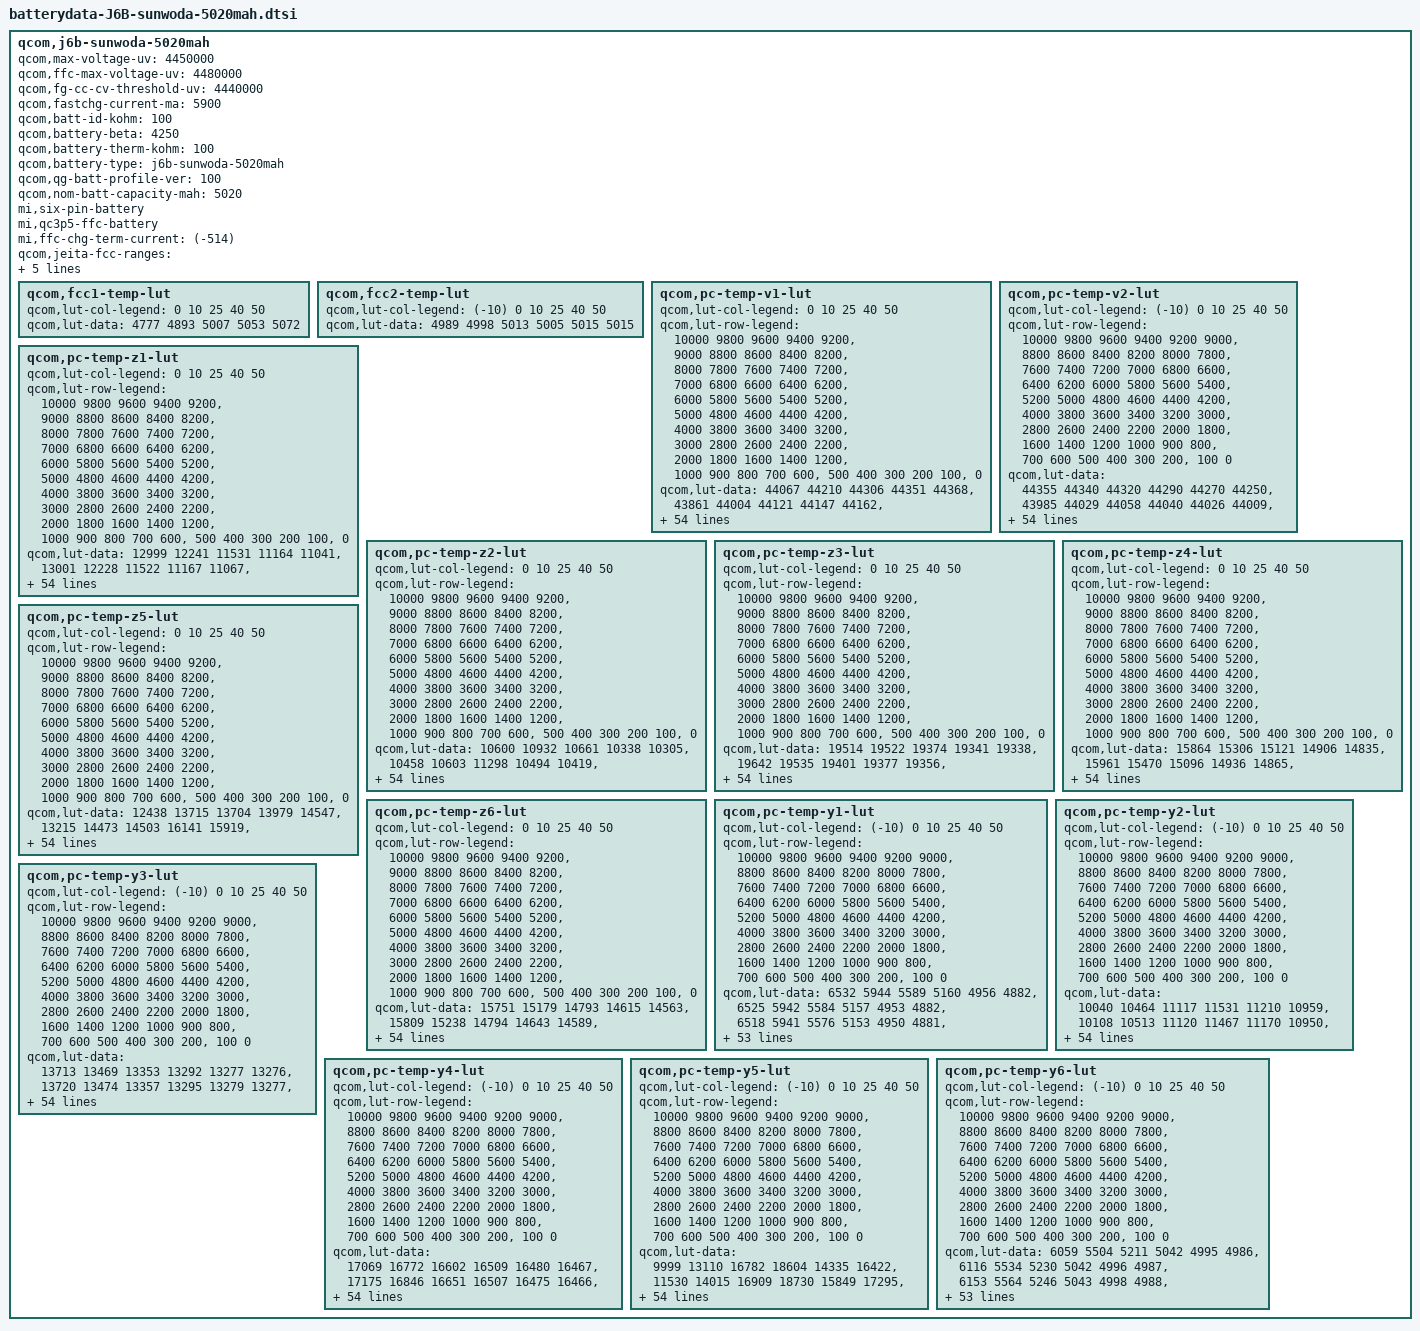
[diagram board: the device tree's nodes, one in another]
/*
 * Copyright (c) 2019, The Linux Foundation. All rights reserved.
 * Copyright (C) 2020 XiaoMi, Inc.
 *
 * This program is free software; you can redistribute it and/or modify
 * it under the terms of the GNU General Public License version 2 and
 * only version 2 as published by the Free Software Foundation.
 *
 * This program is distributed in the hope that it will be useful,
 * but WITHOUT ANY WARRANTY; without even the implied warranty of
 * MERCHANTABILITY or FITNESS FOR A PARTICULAR PURPOSE.  See the
 * GNU General Public License for more details.
 */

qcom,j6b-sunwoda-5020mah {
	/* 4322231_LC_M524_Sunwoda_5020mAH_PM6250_averaged_MasterSlave_Dec20th2019 */
	qcom,max-voltage-uv = <4450000>;
	qcom,ffc-max-voltage-uv = <4480000>;
	qcom,fg-cc-cv-threshold-uv = <4440000>;
	qcom,fastchg-current-ma = <5900>;
	qcom,batt-id-kohm = <100>;
	qcom,battery-beta = <4250>;
	qcom,battery-therm-kohm = <100>;
	qcom,battery-type = "j6b-sunwoda-5020mah";
	qcom,qg-batt-profile-ver = <100>;
	qcom,nom-batt-capacity-mah = <5020>;
	mi,six-pin-battery;
	mi,qc3p5-ffc-battery;
	mi,ffc-chg-term-current = <(-514)>;

	qcom,jeita-fcc-ranges = <0  50   900000
				51  100  2300000
				101 150  3300000
				151 450  5900000
				451 580  2300000>;

	qcom,jeita-fv-ranges = <0   50   4450000
				51  100  4450000
				101 150  4450000
				151 450  4480000
				451 580  4100000>;

	qcom,step-chg-ranges = <3001000  4250000  6000000
				4250001  4450000  4900000
				4450001  4480000  3900000>;

	qcom,fcc1-temp-lut {
		qcom,lut-col-legend = <0 10 25 40 50>;
		qcom,lut-data = <4777 4893 5007 5053 5072>;
	};

	qcom,fcc2-temp-lut {
		qcom,lut-col-legend = <(-10) 0 10 25 40 50>;
		qcom,lut-data = <4989 4998 5013 5005 5015 5015>;
	};

	qcom,pc-temp-v1-lut {
		qcom,lut-col-legend = <0 10 25 40 50>;
		qcom,lut-row-legend = <10000 9800 9600 9400 9200>,
			<9000 8800 8600 8400 8200>,
			<8000 7800 7600 7400 7200>,
			<7000 6800 6600 6400 6200>,
			<6000 5800 5600 5400 5200>,
			<5000 4800 4600 4400 4200>,
			<4000 3800 3600 3400 3200>,
			<3000 2800 2600 2400 2200>,
			<2000 1800 1600 1400 1200>,
			<1000 900 800 700 600>,
			<500 400 300 200 100>,
			<0>;
		qcom,lut-data = <44067 44210 44306 44351 44368>,
			<43861 44004 44121 44147 44162>,
			<43640 43794 43925 43950 43963>,
			<43411 43583 43717 43748 43762>,
			<43173 43361 43496 43539 43553>,
			<42929 43123 43266 43324 43339>,
			<42688 42877 43027 43095 43114>,
			<42445 42633 42783 42854 42878>,
			<42207 42387 42539 42611 42637>,
			<41973 42145 42294 42365 42392>,
			<41744 41910 42051 42118 42145>,
			<41520 41679 41810 41878 41902>,
			<41299 41453 41573 41640 41660>,
			<41084 41229 41343 41406 41425>,
			<40873 41012 41119 41176 41198>,
			<40668 40803 40902 40953 40978>,
			<40467 40599 40694 40738 40763>,
			<40265 40404 40492 40531 40553>,
			<40072 40216 40301 40335 40353>,
			<39902 40032 40120 40157 40172>,
			<39753 39853 39927 39974 39989>,
			<39603 39677 39696 39742 39766>,
			<39440 39478 39456 39478 39507>,
			<39269 39208 39240 39261 39288>,
			<39102 38954 39036 39085 39113>,
			<38927 38811 38877 38936 38963>,
			<38769 38714 38769 38814 38835>,
			<38656 38636 38682 38710 38724>,
			<38569 38569 38595 38610 38617>,
			<38499 38510 38512 38509 38509>,
			<38443 38454 38436 38416 38410>,
			<38397 38400 38365 38333 38325>,
			<38357 38349 38299 38256 38249>,
			<38322 38301 38238 38187 38177>,
			<38290 38255 38181 38124 38108>,
			<38256 38213 38127 38064 38041>,
			<38222 38176 38080 38007 37974>,
			<38179 38134 38034 37949 37906>,
			<38113 38067 37967 37876 37823>,
			<38026 37973 37872 37777 37718>,
			<37923 37866 37763 37666 37602>,
			<37789 37739 37644 37551 37481>,
			<37638 37593 37508 37421 37347>,
			<37464 37415 37340 37259 37184>,
			<37343 37262 37192 37117 37049>,
			<37244 37163 37097 37025 36971>,
			<37203 37137 37069 37002 36943>,
			<37171 37123 37048 36982 36927>,
			<37140 37094 37030 36965 36904>,
			<37081 37047 36976 36904 36833>,
			<36869 36828 36724 36638 36547>,
			<36411 36379 36276 36194 36103>,
			<35819 35795 35687 35615 35521>,
			<35010 34998 34879 34820 34728>,
			<33721 33737 33606 33581 33488>,
			<30000 30000 30000 30000 30000>;
	};

	qcom,pc-temp-v2-lut {
		qcom,lut-col-legend = <(-10) 0 10 25 40 50>;
		qcom,lut-row-legend = <10000 9800 9600 9400 9200 9000>,
			<8800 8600 8400 8200 8000 7800>,
			<7600 7400 7200 7000 6800 6600>,
			<6400 6200 6000 5800 5600 5400>,
			<5200 5000 4800 4600 4400 4200>,
			<4000 3800 3600 3400 3200 3000>,
			<2800 2600 2400 2200 2000 1800>,
			<1600 1400 1200 1000 900 800>,
			<700 600 500 400 300 200>,
			<100 0>;
		qcom,lut-data = <44355 44340 44320 44290 44270 44250>,
			<43985 44029 44058 44040 44026 44009>,
			<43650 43745 43809 43799 43790 43776>,
			<43359 43493 43577 43569 43565 43552>,
			<43109 43273 43363 43351 43350 43339>,
			<42862 43050 43143 43129 43131 43120>,
			<42590 42805 42902 42889 42895 42886>,
			<42316 42549 42651 42642 42653 42645>,
			<42065 42291 42402 42397 42409 42403>,
			<41828 42029 42151 42154 42164 42159>,
			<41613 41768 41904 41913 41921 41916>,
			<41436 41494 41661 41673 41682 41677>,
			<41269 41232 41423 41436 41445 41441>,
			<41057 41048 41191 41205 41214 41211>,
			<40782 40931 40966 40980 40990 40986>,
			<40477 40790 40753 40762 40772 40767>,
			<40138 40515 40565 40550 40561 40556>,
			<39778 40156 40382 40344 40358 40352>,
			<39502 39873 40164 40148 40163 40158>,
			<39295 39648 39901 39967 39982 39978>,
			<39099 39436 39642 39771 39787 39785>,
			<38862 39216 39407 39522 39547 39549>,
			<38624 39002 39186 39253 39292 39300>,
			<38470 38804 38992 39041 39081 39092>,
			<38372 38618 38818 38870 38901 38912>,
			<38293 38450 38662 38722 38746 38756>,
			<38221 38290 38524 38591 38615 38624>,
			<38157 38147 38400 38476 38502 38508>,
			<38098 38062 38285 38368 38397 38403>,
			<38043 38012 38176 38267 38301 38306>,
			<37989 37970 38077 38175 38214 38216>,
			<37929 37926 37982 38094 38134 38136>,
			<37867 37883 37897 38019 38059 38059>,
			<37801 37838 37838 37948 37984 37980>,
			<37733 37792 37799 37880 37909 37898>,
			<37661 37742 37762 37812 37828 37809>,
			<37584 37685 37725 37739 37731 37700>,
			<37503 37623 37686 37662 37625 37583>,
			<37421 37551 37631 37582 37529 37479>,
			<37337 37471 37553 37501 37441 37387>,
			<37255 37378 37455 37412 37348 37293>,
			<37179 37264 37328 37306 37247 37190>,
			<37108 37133 37180 37184 37134 37077>,
			<37040 36997 37026 37040 36992 36936>,
			<36968 36875 36896 36925 36886 36833>,
			<36881 36788 36811 36870 36838 36788>,
			<36826 36751 36773 36852 36826 36775>,
			<36763 36714 36733 36832 36810 36759>,
			<36689 36669 36676 36795 36780 36728>,
			<36577 36585 36573 36708 36691 36621>,
			<36371 36391 36336 36413 36374 36275>,
			<35995 35997 35894 35911 35878 35770>,
			<35394 35373 35269 35245 35221 35101>,
			<34516 34482 34387 34317 34298 34172>,
			<33069 32970 32916 32764 32899 32759>,
			<28712 28026 28771 27555 28520 28438>;
	};

	qcom,pc-temp-z1-lut {
		qcom,lut-col-legend = <0 10 25 40 50>;
		qcom,lut-row-legend = <10000 9800 9600 9400 9200>,
			<9000 8800 8600 8400 8200>,
			<8000 7800 7600 7400 7200>,
			<7000 6800 6600 6400 6200>,
			<6000 5800 5600 5400 5200>,
			<5000 4800 4600 4400 4200>,
			<4000 3800 3600 3400 3200>,
			<3000 2800 2600 2400 2200>,
			<2000 1800 1600 1400 1200>,
			<1000 900 800 700 600>,
			<500 400 300 200 100>,
			<0>;
		qcom,lut-data = <12999 12241 11531 11164 11041>,
			<13001 12228 11522 11167 11067>,
			<13008 12216 11513 11162 11055>,
			<13008 12203 11506 11157 11045>,
			<12987 12186 11492 11152 11042>,
			<12957 12164 11478 11145 11039>,
			<12933 12141 11465 11139 11035>,
			<12910 12122 11453 11133 11032>,
			<12899 12107 11441 11129 11029>,
			<12902 12093 11430 11125 11027>,
			<12906 12078 11423 11122 11025>,
			<12902 12063 11419 11121 11024>,
			<12868 12052 11417 11121 11024>,
			<12828 12041 11416 11120 11023>,
			<12804 12033 11416 11120 11023>,
			<12786 12030 11416 11119 11024>,
			<12767 12028 11416 11119 11024>,
			<12744 12025 11417 11120 11026>,
			<12724 12019 11418 11121 11027>,
			<12717 12015 11420 11122 11028>,
			<12713 12017 11423 11123 11029>,
			<12712 12023 11426 11125 11030>,
			<12718 12028 11429 11126 11031>,
			<12735 12031 11433 11128 11032>,
			<12744 12035 11436 11129 11034>,
			<12745 12040 11440 11131 11036>,
			<12744 12046 11444 11133 11038>,
			<12741 12050 11449 11137 11041>,
			<12738 12054 11453 11141 11044>,
			<12736 12057 11457 11145 11048>,
			<12747 12060 11462 11149 11051>,
			<12764 12063 11468 11153 11054>,
			<12768 12068 11474 11157 11058>,
			<12758 12073 11480 11162 11062>,
			<12749 12079 11485 11166 11065>,
			<12752 12087 11491 11170 11068>,
			<12767 12099 11497 11174 11072>,
			<12781 12111 11502 11178 11075>,
			<12797 12119 11509 11182 11078>,
			<12813 12125 11517 11186 11082>,
			<12826 12132 11525 11190 11086>,
			<12847 12140 11533 11195 11089>,
			<12858 12152 11542 11200 11092>,
			<12870 12177 11558 11205 11096>,
			<12870 12200 11579 11214 11100>,
			<12891 12195 11585 11217 11104>,
			<12871 12189 11587 11216 11103>,
			<12883 12199 11588 11219 11103>,
			<12901 12186 11592 11221 11106>,
			<12895 12212 11601 11227 11109>,
			<12889 12207 11611 11233 11114>,
			<12906 12228 11622 11241 11120>,
			<12923 12251 11635 11250 11129>,
			<12945 12273 11653 11265 11141>,
			<12945 12273 11653 11265 11141>,
			<12945 12273 11653 11265 11141>;
	};

	qcom,pc-temp-z2-lut {
		qcom,lut-col-legend = <0 10 25 40 50>;
		qcom,lut-row-legend = <10000 9800 9600 9400 9200>,
			<9000 8800 8600 8400 8200>,
			<8000 7800 7600 7400 7200>,
			<7000 6800 6600 6400 6200>,
			<6000 5800 5600 5400 5200>,
			<5000 4800 4600 4400 4200>,
			<4000 3800 3600 3400 3200>,
			<3000 2800 2600 2400 2200>,
			<2000 1800 1600 1400 1200>,
			<1000 900 800 700 600>,
			<500 400 300 200 100>,
			<0>;
		qcom,lut-data = <10600 10932 10661 10338 10305>,
			<10458 10603 11298 10494 10419>,
			<10419 10572 11598 10572 10488>,
			<10398 10561 11457 10595 10520>,
			<10369 10544 10904 10573 10502>,
			<10342 10508 10605 10534 10468>,
			<10334 10465 10555 10488 10437>,
			<10331 10436 10516 10429 10386>,
			<10330 10411 10489 10407 10356>,
			<10335 10400 10468 10414 10361>,
			<10342 10401 10460 10422 10371>,
			<10347 10405 10471 10418 10375>,
			<10351 10414 10494 10406 10387>,
			<10356 10449 10559 10401 10393>,
			<10363 10485 10728 10411 10298>,
			<10373 10504 10847 10423 10173>,
			<10387 10521 10901 10437 10164>,
			<10412 10543 10939 10459 10195>,
			<10446 10584 10903 10462 10224>,
			<10483 10616 10725 10399 10244>,
			<10529 10619 10636 10338 10269>,
			<10561 10619 10716 10447 10379>,
			<10567 10622 10816 10724 10634>,
			<10571 10649 10814 10802 10737>,
			<10576 10679 10727 10578 10577>,
			<10592 10679 10669 10373 10402>,
			<10611 10666 10664 10400 10402>,
			<10625 10658 10668 10490 10448>,
			<10637 10666 10690 10576 10500>,
			<10646 10679 10753 10718 10589>,
			<10654 10690 10787 10820 10659>,
			<10660 10699 10776 10767 10609>,
			<10669 10707 10757 10646 10462>,
			<10680 10712 10746 10592 10364>,
			<10693 10716 10736 10567 10302>,
			<10707 10721 10731 10555 10269>,
			<10723 10726 10741 10578 10297>,
			<10741 10733 10762 10635 10375>,
			<10761 10748 10791 10698 10452>,
			<10785 10772 10839 10797 10534>,
			<10812 10795 10872 10858 10608>,
			<10844 10814 10883 10845 10674>,
			<10900 10839 10888 10815 10718>,
			<10995 10882 10889 10768 10708>,
			<10674 11187 10965 10768 10623>,
			<10501 11256 11003 10695 10514>,
			<10449 11268 10974 10612 10493>,
			<10405 11276 10964 10596 10510>,
			<10391 11360 10945 10633 10533>,
			<10352 11325 11013 10716 10644>,
			<10274 11331 11106 10619 10462>,
			<10194 11178 11012 10408 10235>,
			<10056 11002 10931 10361 10175>,
			<9922 10822 10834 10307 10152>,
			<9922 10822 10834 10307 10152>,
			<9922 10822 10834 10307 10152>;
	};

	qcom,pc-temp-z3-lut {
		qcom,lut-col-legend = <0 10 25 40 50>;
		qcom,lut-row-legend = <10000 9800 9600 9400 9200>,
			<9000 8800 8600 8400 8200>,
			<8000 7800 7600 7400 7200>,
			<7000 6800 6600 6400 6200>,
			<6000 5800 5600 5400 5200>,
			<5000 4800 4600 4400 4200>,
			<4000 3800 3600 3400 3200>,
			<3000 2800 2600 2400 2200>,
			<2000 1800 1600 1400 1200>,
			<1000 900 800 700 600>,
			<500 400 300 200 100>,
			<0>;
		qcom,lut-data = <19514 19522 19374 19341 19338>,
			<19642 19535 19401 19377 19356>,
			<19727 19562 19425 19402 19378>,
			<19776 19591 19447 19417 19395>,
			<19807 19614 19476 19426 19405>,
			<19827 19631 19492 19432 19413>,
			<19835 19643 19498 19434 19414>,
			<19840 19646 19501 19435 19414>,
			<19842 19647 19500 19435 19414>,
			<19835 19647 19494 19433 19412>,
			<19823 19638 19487 19429 19409>,
			<19819 19621 19477 19422 19407>,
			<19817 19610 19466 19414 19405>,
			<19816 19601 19465 19408 19402>,
			<19815 19594 19472 19405 19394>,
			<19815 19589 19474 19403 19385>,
			<19815 19584 19468 19399 19380>,
			<19804 19578 19458 19395 19378>,
			<19786 19567 19449 19390 19374>,
			<19771 19558 19434 19380 19368>,
			<19755 19560 19427 19372 19361>,
			<19745 19567 19442 19378 19363>,
			<19751 19575 19464 19394 19371>,
			<19766 19588 19465 19398 19374>,
			<19773 19600 19453 19380 19357>,
			<19776 19599 19440 19361 19339>,
			<19777 19590 19428 19356 19340>,
			<19775 19581 19419 19354 19348>,
			<19766 19573 19418 19355 19360>,
			<19756 19566 19422 19380 19387>,
			<19749 19565 19428 19402 19410>,
			<19742 19566 19438 19406 19408>,
			<19734 19568 19449 19408 19397>,
			<19725 19570 19451 19408 19388>,
			<19716 19572 19452 19400 19377>,
			<19709 19572 19451 19391 19368>,
			<19702 19569 19447 19384 19362>,
			<19695 19564 19440 19377 19357>,
			<19688 19559 19435 19374 19354>,
			<19680 19552 19433 19373 19353>,
			<19669 19545 19430 19373 19352>,
			<19652 19537 19426 19372 19356>,
			<19631 19527 19421 19370 19364>,
			<19602 19515 19415 19368 19365>,
			<19379 19467 19400 19363 19363>,
			<19324 19446 19387 19357 19345>,
			<19321 19430 19385 19345 19341>,
			<19314 19371 19387 19345 19332>,
			<19308 19357 19378 19334 19327>,
			<19307 19315 19363 19328 19323>,
			<19309 19325 19350 19347 19350>,
			<19314 19313 19363 19364 19359>,
			<19320 19308 19354 19359 19362>,
			<19326 19306 19339 19354 19354>,
			<19326 19306 19339 19354 19354>,
			<19326 19306 19339 19354 19354>;
	};

	qcom,pc-temp-z4-lut {
		qcom,lut-col-legend = <0 10 25 40 50>;
		qcom,lut-row-legend = <10000 9800 9600 9400 9200>,
			<9000 8800 8600 8400 8200>,
			<8000 7800 7600 7400 7200>,
			<7000 6800 6600 6400 6200>,
			<6000 5800 5600 5400 5200>,
			<5000 4800 4600 4400 4200>,
			<4000 3800 3600 3400 3200>,
			<3000 2800 2600 2400 2200>,
			<2000 1800 1600 1400 1200>,
			<1000 900 800 700 600>,
			<500 400 300 200 100>,
			<0>;
		qcom,lut-data = <15864 15306 15121 14906 14835>,
			<15961 15470 15096 14936 14865>,
			<15842 15446 15064 14913 14858>,
			<15712 15327 15025 14888 14848>,
			<15577 15215 14974 14860 14830>,
			<15447 15130 14927 14831 14805>,
			<15347 15056 14888 14808 14785>,
			<15263 14999 14854 14788 14768>,
			<15195 14951 14827 14769 14753>,
			<15141 14916 14805 14748 14737>,
			<15096 14891 14787 14732 14724>,
			<15052 14871 14773 14727 14715>,
			<15010 14848 14761 14724 14709>,
			<14972 14820 14742 14720 14705>,
			<14936 14798 14718 14712 14704>,
			<14902 14785 14703 14704 14703>,
			<14881 14776 14698 14697 14700>,
			<14873 14774 14696 14691 14693>,
			<14867 14773 14696 14688 14688>,
			<14856 14773 14703 14687 14683>,
			<14835 14768 14712 14686 14680>,
			<14819 14758 14724 14699 14690>,
			<14810 14755 14742 14735 14731>,
			<14804 14806 14773 14771 14769>,
			<14804 14867 14826 14811 14803>,
			<14829 14876 14855 14838 14826>,
			<14858 14877 14854 14836 14822>,
			<14865 14877 14851 14826 14800>,
			<14867 14870 14845 14811 14774>,
			<14868 14855 14828 14772 14731>,
			<14863 14841 14807 14735 14696>,
			<14853 14826 14783 14715 14688>,
			<14843 14812 14760 14701 14684>,
			<14832 14799 14746 14697 14683>,
			<14821 14788 14736 14696 14684>,
			<14809 14779 14732 14695 14685>,
			<14797 14770 14732 14696 14686>,
			<14787 14766 14732 14699 14687>,
			<14778 14766 14734 14704 14691>,
			<14770 14767 14743 14715 14705>,
			<14766 14766 14749 14723 14716>,
			<14763 14756 14741 14719 14708>,
			<14758 14744 14731 14714 14696>,
			<14747 14734 14726 14712 14697>,
			<14860 14701 14703 14698 14687>,
			<14896 14693 14684 14679 14676>,
			<14895 14698 14675 14680 14673>,
			<14897 14750 14660 14666 14664>,
			<14895 14758 14653 14655 14645>,
			<14895 14803 14665 14652 14640>,
			<14896 14799 14704 14668 14654>,
			<14913 14827 14698 14664 14660>,
			<14915 14835 14711 14672 14661>,
			<14926 14844 14729 14678 14669>,
			<14926 14844 14729 14678 14669>,
			<14926 14844 14729 14678 14669>;
	};

	qcom,pc-temp-z5-lut {
		qcom,lut-col-legend = <0 10 25 40 50>;
		qcom,lut-row-legend = <10000 9800 9600 9400 9200>,
			<9000 8800 8600 8400 8200>,
			<8000 7800 7600 7400 7200>,
			<7000 6800 6600 6400 6200>,
			<6000 5800 5600 5400 5200>,
			<5000 4800 4600 4400 4200>,
			<4000 3800 3600 3400 3200>,
			<3000 2800 2600 2400 2200>,
			<2000 1800 1600 1400 1200>,
			<1000 900 800 700 600>,
			<500 400 300 200 100>,
			<0>;
		qcom,lut-data = <12438 13715 13704 13979 14547>,
			<13215 14473 14503 16141 15919>,
			<13923 14966 15160 17678 17858>,
			<14494 15479 15849 18711 19434>,
			<14923 16038 17058 19369 20524>,
			<15301 16690 17991 19870 21360>,
			<15711 17389 18640 20299 21840>,
			<16137 18115 19158 20654 22118>,
			<16510 18920 19447 21136 22477>,
			<16777 19381 19700 22154 23381>,
			<17023 19435 19828 23017 24593>,
			<17413 19441 20047 22874 25599>,
			<18083 19703 20530 22269 26609>,
			<18959 20883 21744 22062 27032>,
			<20162 22286 24731 22929 25930>,
			<21775 23607 26806 24159 24488>,
			<23014 24872 27474 25144 24664>,
			<23736 25164 27740 26094 26093>,
			<24346 24599 27125 26327 27094>,
			<25013 24066 24985 25311 27096>,
			<25693 25509 24501 24311 27102>,
			<26742 30518 34468 28086 28756>,
			<31181 36239 47775 37539 32505>,
			<39568 44543 48015 40056 33800>,
			<45630 51542 38471 30498 26530>,
			<49906 50427 30039 20751 18438>,
			<52728 42893 25355 18387 17408>,
			<52421 36634 22164 17060 17136>,
			<49564 33223 21680 16969 17418>,
			<46544 30887 21633 19248 23310>,
			<44329 30599 21626 22359 29396>,
			<42305 31078 23213 25322 30065>,
			<40690 31849 26330 28331 29815>,
			<39167 33695 29546 29832 29379>,
			<38244 36485 33526 30683 28572>,
			<38219 38259 35560 31091 27882>,
			<38334 39506 35581 30768 27716>,
			<38537 40184 35467 29955 27630>,
			<39815 40074 35058 29183 27310>,
			<41392 39625 33653 28448 25818>,
			<41111 38894 31965 27556 24656>,
			<38043 36766 30153 25482 24930>,
			<35977 35425 28380 23478 25589>,
			<34882 35081 26836 23221 26616>,
			<17355 35841 27790 23895 26917>,
			<13633 32615 27665 23865 21800>,
			<13519 27928 27520 20501 20481>,
			<13220 18108 30310 22108 19299>,
			<13050 16748 27903 21245 22075>,
			<13019 13626 23035 20616 22139>,
			<13110 14094 17313 20664 25291>,
			<12977 13261 17425 21526 22834>,
			<12907 12948 15909 18937 21431>,
			<12724 12664 14395 16720 17436>,
			<12724 12664 14395 16720 17436>,
			<12724 12664 14395 16720 17436>;
	};

	qcom,pc-temp-z6-lut {
		qcom,lut-col-legend = <0 10 25 40 50>;
		qcom,lut-row-legend = <10000 9800 9600 9400 9200>,
			<9000 8800 8600 8400 8200>,
			<8000 7800 7600 7400 7200>,
			<7000 6800 6600 6400 6200>,
			<6000 5800 5600 5400 5200>,
			<5000 4800 4600 4400 4200>,
			<4000 3800 3600 3400 3200>,
			<3000 2800 2600 2400 2200>,
			<2000 1800 1600 1400 1200>,
			<1000 900 800 700 600>,
			<500 400 300 200 100>,
			<0>;
		qcom,lut-data = <15751 15179 14793 14615 14563>,
			<15809 15238 14794 14643 14589>,
			<15768 15228 14791 14647 14598>,
			<15719 15176 14786 14647 14601>,
			<15654 15126 14774 14641 14598>,
			<15585 15086 14760 14629 14591>,
			<15530 15049 14745 14621 14585>,
			<15483 15019 14729 14612 14578>,
			<15442 14994 14714 14603 14571>,
			<15405 14971 14700 14593 14563>,
			<15371 14948 14687 14584 14555>,
			<15342 14927 14674 14577 14550>,
			<15317 14908 14663 14571 14546>,
			<15293 14888 14655 14566 14542>,
			<15271 14873 14648 14560 14537>,
			<15250 14864 14642 14555 14531>,
			<15231 14857 14636 14550 14526>,
			<15213 14851 14630 14546 14522>,
			<15198 14843 14626 14541 14518>,
			<15181 14839 14621 14534 14512>,
			<15162 14839 14620 14530 14507>,
			<15151 14840 14631 14540 14513>,
			<15153 14843 14652 14565 14537>,
			<15158 14873 14669 14580 14552>,
			<15166 14907 14684 14586 14557>,
			<15181 14910 14691 14590 14559>,
			<15195 14908 14688 14588 14558>,
			<15195 14904 14682 14582 14553>,
			<15191 14897 14677 14578 14549>,
			<15186 14889 14673 14574 14547>,
			<15182 14883 14669 14571 14544>,
			<15178 14879 14665 14567 14540>,
			<15173 14875 14661 14563 14534>,
			<15165 14872 14658 14559 14528>,
			<15157 14870 14656 14555 14523>,
			<15150 14867 14654 14552 14520>,
			<15144 14864 14651 14549 14517>,
			<15142 14862 14649 14546 14514>,
			<15141 14863 14649 14546 14514>,
			<15141 14864 14653 14551 14519>,
			<15140 14864 14656 14555 14523>,
			<15139 14861 14652 14553 14523>,
			<15136 14856 14647 14550 14522>,
			<15129 14853 14644 14549 14524>,
			<15081 14827 14631 14542 14519>,
			<15071 14815 14619 14531 14505>,
			<15068 14810 14614 14526 14502>,
			<15064 14803 14609 14519 14493>,
			<15062 14800 14602 14509 14483>,
			<15068 14803 14602 14505 14478>,
			<15080 14812 14614 14523 14500>,
			<15096 14823 14622 14533 14510>,
			<15113 14834 14626 14536 14514>,
			<15138 14849 14633 14540 14517>,
			<15138 14849 14633 14540 14517>,
			<15138 14849 14633 14540 14517>;
	};

	qcom,pc-temp-y1-lut {
		qcom,lut-col-legend = <(-10) 0 10 25 40 50>;
		qcom,lut-row-legend = <10000 9800 9600 9400 9200 9000>,
			<8800 8600 8400 8200 8000 7800>,
			<7600 7400 7200 7000 6800 6600>,
			<6400 6200 6000 5800 5600 5400>,
			<5200 5000 4800 4600 4400 4200>,
			<4000 3800 3600 3400 3200 3000>,
			<2800 2600 2400 2200 2000 1800>,
			<1600 1400 1200 1000 900 800>,
			<700 600 500 400 300 200>,
			<100 0>;
		qcom,lut-data = <6532 5944 5589 5160 4956 4882>,
			<6525 5942 5584 5157 4953 4882>,
			<6518 5941 5576 5153 4950 4881>,
			<6512 5940 5567 5148 4948 4880>,
			<6506 5939 5559 5144 4945 4879>,
			<6500 5938 5552 5140 4943 4879>,
			<6494 5938 5546 5137 4942 4878>,
			<6488 5939 5540 5134 4940 4877>,
			<6487 5938 5538 5132 4939 4877>,
			<6494 5934 5539 5130 4938 4876>,
			<6499 5932 5539 5129 4937 4876>,
			<6505 5941 5537 5127 4936 4876>,
			<6515 5954 5535 5126 4934 4876>,
			<6517 5955 5532 5126 4934 4876>,
			<6519 5943 5529 5126 4934 4876>,
			<6521 5935 5527 5126 4935 4876>,
			<6522 5945 5528 5125 4935 4876>,
			<6522 5964 5531 5125 4935 4876>,
			<6520 5969 5531 5125 4935 4876>,
			<6506 5962 5531 5126 4935 4876>,
			<6495 5956 5530 5128 4935 4876>,
			<6497 5958 5533 5131 4937 4877>,
			<6500 5959 5538 5135 4939 4877>,
			<6500 5960 5540 5138 4940 4878>,
			<6498 5960 5540 5140 4940 4878>,
			<6496 5960 5541 5143 4941 4879>,
			<6489 5964 5545 5146 4943 4881>,
			<6478 5969 5551 5150 4947 4883>,
			<6474 5968 5553 5155 4950 4885>,
			<6473 5963 5552 5160 4952 4887>,
			<6473 5959 5552 5165 4955 4889>,
			<6471 5953 5554 5171 4959 4891>,
			<6470 5944 5558 5176 4963 4895>,
			<6469 5938 5561 5182 4966 4898>,
			<6473 5934 5566 5187 4969 4900>,
			<6479 5932 5571 5191 4972 4902>,
			<6483 5932 5577 5196 4974 4904>,
			<6485 5933 5582 5201 4976 4905>,
			<6489 5935 5586 5206 4978 4907>,
			<6496 5940 5589 5211 4980 4908>,
			<6498 5944 5590 5216 4983 4910>,
			<6476 5937 5590 5221 4985 4912>,
			<6447 5929 5589 5228 4987 4915>,
			<6455 5927 5597 5239 4990 4918>,
			<6466 5934 5594 5247 4995 4920>,
			<6494 5955 5602 5258 4999 4922>,
			<6493 5957 5595 5256 5000 4922>,
			<6517 5963 5613 5253 4998 4922>,
			<6480 5974 5605 5254 4998 4921>,
			<6461 5944 5605 5256 4998 4923>,
			<6504 5955 5624 5258 4999 4923>,
			<6582 5964 5603 5270 5004 4928>,
			<6647 5978 5622 5294 5012 4934>,
			<6758 6045 5639 5316 5023 4941>,
			<6758 6045 5639 5316 5023 4941>,
			<6758 6045 5639 5316 5023 4941>;
	};

	qcom,pc-temp-y2-lut {
		qcom,lut-col-legend = <(-10) 0 10 25 40 50>;
		qcom,lut-row-legend = <10000 9800 9600 9400 9200 9000>,
			<8800 8600 8400 8200 8000 7800>,
			<7600 7400 7200 7000 6800 6600>,
			<6400 6200 6000 5800 5600 5400>,
			<5200 5000 4800 4600 4400 4200>,
			<4000 3800 3600 3400 3200 3000>,
			<2800 2600 2400 2200 2000 1800>,
			<1600 1400 1200 1000 900 800>,
			<700 600 500 400 300 200>,
			<100 0>;
		qcom,lut-data = <10040 10464 11117 11531 11210 10959>,
			<10108 10513 11120 11467 11170 10950>,
			<10174 10587 11122 11404 11129 10936>,
			<10237 10667 11122 11345 11091 10920>,
			<10296 10734 11122 11294 11058 10903>,
			<10348 10770 11122 11254 11033 10890>,
			<10389 10780 11111 11223 10988 10878>,
			<10430 10787 11093 11199 10929 10866>,
			<10520 10779 11082 11190 10908 10851>,
			<10743 10723 11075 11190 10899 10827>,
			<10889 10685 11072 11192 10894 10808>,
			<10824 10831 11085 11193 10889 10796>,
			<10708 11080 11116 11199 10890 10787>,
			<10707 11116 11148 11209 10906 10787>,
			<10896 10987 11186 11239 10952 10802>,
			<11040 10892 11230 11280 10996 10821>,
			<10647 10958 11290 11334 11024 10850>,
			<9901 11093 11352 11399 11053 10895>,
			<9695 11181 11380 11460 11111 10949>,
			<9687 11239 11395 11526 11234 11023>,
			<9683 11281 11407 11561 11325 11095>,
			<9678 11315 11419 11536 11349 11169>,
			<9674 11343 11432 11490 11359 11231>,
			<9672 11336 11448 11480 11350 11230>,
			<9670 11215 11469 11490 11299 11165>,
			<9669 11018 11494 11506 11269 11121>,
			<9668 10615 11529 11535 11297 11140>,
			<9667 10069 11564 11579 11339 11182>,
			<9667 9855 11560 11614 11359 11232>,
			<9666 9789 11500 11642 11378 11308>,
			<9665 9749 11456 11670 11399 11368>,
			<9665 9718 11452 11711 11453 11419>,
			<9664 9695 11449 11751 11538 11476>,
			<9664 9683 11436 11758 11601 11500>,
			<9663 9677 11377 11746 11659 11566>,
			<9663 9672 11309 11730 11687 11604>,
			<9663 9669 11258 11709 11630 11545>,
			<9662 9666 11204 11675 11531 11445>,
			<9662 9664 11128 11632 11489 11382>,
			<9662 9662 11020 11567 11466 11319>,
			<9662 9661 10852 11505 11445 11266>,
			<9662 9661 10355 11466 11422 11231>,
			<9661 9660 9857 11425 11394 11197>,
			<9660 9660 9764 11339 11302 11160>,
			<9660 9659 9718 11226 11164 11040>,
			<9659 9659 9713 11213 11037 10897>,
			<9659 9659 9703 11206 11060 10864>,
			<9658 9658 9690 11162 11092 10925>,
			<9657 9657 9681 11149 11103 10971>,
			<9655 9657 9675 11147 11118 10956>,
			<9652 9656 9670 11108 11032 10866>,
			<9650 9654 9664 10982 10998 10784>,
			<9649 9652 9659 10866 10883 10670>,
			<9648 9650 9656 10756 10778 10591>,
			<9648 9650 9656 10756 10778 10591>,
			<9648 9650 9656 10756 10778 10591>;
	};

	qcom,pc-temp-y3-lut {
		qcom,lut-col-legend = <(-10) 0 10 25 40 50>;
		qcom,lut-row-legend = <10000 9800 9600 9400 9200 9000>,
			<8800 8600 8400 8200 8000 7800>,
			<7600 7400 7200 7000 6800 6600>,
			<6400 6200 6000 5800 5600 5400>,
			<5200 5000 4800 4600 4400 4200>,
			<4000 3800 3600 3400 3200 3000>,
			<2800 2600 2400 2200 2000 1800>,
			<1600 1400 1200 1000 900 800>,
			<700 600 500 400 300 200>,
			<100 0>;
		qcom,lut-data = <13713 13469 13353 13292 13277 13276>,
			<13720 13474 13357 13295 13279 13277>,
			<13723 13480 13360 13297 13281 13279>,
			<13723 13485 13364 13299 13283 13280>,
			<13721 13490 13367 13300 13285 13281>,
			<13717 13492 13370 13301 13286 13282>,
			<13703 13491 13371 13299 13286 13283>,
			<13682 13490 13371 13298 13286 13284>,
			<13673 13488 13372 13298 13287 13284>,
			<13670 13481 13372 13303 13288 13285>,
			<13665 13474 13372 13306 13288 13285>,
			<13621 13468 13371 13306 13289 13286>,
			<13551 13462 13368 13306 13289 13286>,
			<13535 13458 13364 13306 13290 13287>,
			<13540 13445 13359 13308 13293 13289>,
			<13544 13433 13356 13310 13296 13290>,
			<13528 13430 13359 13308 13298 13291>,
			<13498 13426 13362 13304 13299 13292>,
			<13492 13421 13362 13304 13299 13292>,
			<13508 13412 13355 13308 13298 13293>,
			<13521 13401 13348 13310 13297 13293>,
			<13512 13389 13343 13307 13294 13290>,
			<13494 13376 13339 13301 13289 13286>,
			<13492 13370 13336 13298 13286 13283>,
			<13513 13368 13333 13296 13283 13281>,
			<13542 13365 13331 13295 13281 13280>,
			<13567 13354 13328 13294 13280 13280>,
			<13594 13338 13326 13294 13280 13279>,
			<13627 13335 13324 13293 13280 13280>,
			<13667 13350 13322 13293 13280 13281>,
			<13710 13369 13321 13292 13281 13281>,
			<13750 13389 13319 13293 13281 13281>,
			<13790 13412 13317 13293 13282 13279>,
			<13832 13441 13317 13293 13282 13279>,
			<13878 13481 13319 13294 13283 13280>,
			<13923 13530 13322 13294 13283 13281>,
			<13963 13593 13327 13294 13283 13281>,
			<13999 13669 13333 13294 13282 13280>,
			<14031 13743 13338 13294 13282 13280>,
			<14058 13818 13341 13294 13283 13281>,
			<14084 13886 13344 13294 13284 13282>,
			<14111 13939 13351 13296 13284 13282>,
			<14141 13982 13360 13298 13285 13282>,
			<14189 14018 13378 13299 13282 13280>,
			<14255 14060 13410 13300 13283 13281>,
			<14284 14063 13412 13305 13286 13286>,
			<14288 14078 13427 13307 13292 13288>,
			<14399 14157 13460 13313 13296 13291>,
			<14554 14236 13499 13318 13298 13293>,
			<14798 14334 13550 13325 13298 13291>,
			<15428 14471 13608 13319 13292 13286>,
			<17054 14723 13720 13320 13294 13287>,
			<20902 15531 13975 13328 13297 13289>,
			<31195 17964 14404 13342 13303 13300>,
			<31195 17964 14404 13342 13303 13300>,
			<31195 17964 14404 13342 13303 13300>;
	};

	qcom,pc-temp-y4-lut {
		qcom,lut-col-legend = <(-10) 0 10 25 40 50>;
		qcom,lut-row-legend = <10000 9800 9600 9400 9200 9000>,
			<8800 8600 8400 8200 8000 7800>,
			<7600 7400 7200 7000 6800 6600>,
			<6400 6200 6000 5800 5600 5400>,
			<5200 5000 4800 4600 4400 4200>,
			<4000 3800 3600 3400 3200 3000>,
			<2800 2600 2400 2200 2000 1800>,
			<1600 1400 1200 1000 900 800>,
			<700 600 500 400 300 200>,
			<100 0>;
		qcom,lut-data = <17069 16772 16602 16509 16480 16467>,
			<17175 16846 16651 16507 16475 16466>,
			<17278 16949 16706 16507 16471 16465>,
			<17367 17054 16757 16508 16469 16464>,
			<17429 17136 16794 16509 16468 16464>,
			<17453 17170 16809 16511 16468 16464>,
			<17438 17161 16801 16516 16470 16464>,
			<17405 17143 16787 16522 16473 16465>,
			<17371 17135 16778 16523 16475 16465>,
			<17327 17131 16772 16523 16478 16467>,
			<17301 17128 16769 16523 16481 16470>,
			<17396 17118 16773 16529 16486 16473>,
			<17564 17102 16782 16539 16491 16477>,
			<17583 17118 16794 16548 16495 16480>,
			<17429 17239 16816 16555 16498 16483>,
			<17271 17327 16838 16565 16501 16487>,
			<17198 17239 16859 16585 16507 16492>,
			<17143 17069 16876 16612 16517 16499>,
			<17082 16988 16870 16632 16532 16510>,
			<17014 16956 16816 16650 16561 16531>,
			<16949 16925 16755 16659 16578 16544>,
			<16880 16884 16709 16622 16557 16530>,
			<16817 16838 16669 16553 16519 16505>,
			<16800 16784 16641 16521 16497 16488>,
			<16798 16712 16621 16506 16480 16473>,
			<16798 16664 16607 16499 16472 16466>,
			<16801 16656 16600 16501 16475 16467>,
			<16809 16652 16595 16505 16480 16470>,
			<16813 16652 16587 16510 16487 16473>,
			<16814 16663 16575 16516 16494 16478>,
			<16815 16678 16563 16522 16503 16485>,
			<16818 16695 16548 16530 16514 16497>,
			<16824 16714 16535 16538 16523 16510>,
			<16827 16731 16535 16540 16525 16513>,
			<16828 16745 16554 16539 16524 16513>,
			<16829 16758 16578 16538 16524 16513>,
			<16827 16771 16602 16529 16510 16502>,
			<16822 16782 16627 16513 16488 16484>,
			<16821 16788 16647 16509 16480 16478>,
			<16822 16792 16663 16510 16478 16477>,
			<16824 16794 16676 16511 16477 16476>,
			<16834 16783 16688 16516 16480 16479>,
			<16856 16760 16695 16521 16483 16482>,
			<16879 16743 16691 16521 16471 16463>,
			<16898 16737 16690 16523 16466 16453>,
			<16874 16727 16675 16520 16475 16469>,
			<16843 16729 16690 16529 16490 16497>,
			<16860 16748 16720 16549 16516 16528>,
			<16876 16776 16764 16580 16550 16560>,
			<16890 16812 16818 16600 16561 16558>,
			<16955 16828 16842 16564 16491 16482>,
			<17235 16807 16847 16554 16478 16476>,
			<18149 16906 16880 16573 16483 16478>,
			<23403 17810 16965 16613 16496 16485>,
			<23403 17810 16965 16613 16496 16485>,
			<23403 17810 16965 16613 16496 16485>;
	};

	qcom,pc-temp-y5-lut {
		qcom,lut-col-legend = <(-10) 0 10 25 40 50>;
		qcom,lut-row-legend = <10000 9800 9600 9400 9200 9000>,
			<8800 8600 8400 8200 8000 7800>,
			<7600 7400 7200 7000 6800 6600>,
			<6400 6200 6000 5800 5600 5400>,
			<5200 5000 4800 4600 4400 4200>,
			<4000 3800 3600 3400 3200 3000>,
			<2800 2600 2400 2200 2000 1800>,
			<1600 1400 1200 1000 900 800>,
			<700 600 500 400 300 200>,
			<100 0>;
		qcom,lut-data = <9999 13110 16782 18604 14335 16422>,
			<11530 14015 16909 18730 15849 17295>,
			<13236 14971 17083 18569 16856 17914>,
			<14900 15885 17266 18184 17438 18310>,
			<16300 16662 17420 17643 17673 18513>,
			<17217 17208 17506 17010 17642 18552>,
			<17635 17593 17540 15965 17131 18356>,
			<17941 17864 17563 14869 16350 17992>,
			<18623 17839 17532 14760 15941 17635>,
			<20281 17378 17307 15307 15725 17117>,
			<21372 16911 16999 15673 15498 16608>,
			<20589 16486 16619 15322 15088 16176>,
			<19148 16087 16156 14745 14680 15803>,
			<19340 16343 15695 14614 14699 15640>,
			<23174 17797 15167 14631 15216 15762>,
			<26112 19021 14897 14640 15561 15885>,
			<22904 19390 16588 14375 15548 15724>,
			<16776 19676 19517 13936 15523 15453>,
			<15333 20152 20633 14175 15502 15383>,
			<16703 20991 21011 16468 15480 15324>,
			<17806 21678 21364 18755 15590 15297>,
			<16510 21953 21954 20004 17213 16720>,
			<13838 22169 22528 20918 19610 18952>,
			<12898 22741 22688 21045 19886 19339>,
			<12754 24607 22697 20705 18684 18931>,
			<12668 25937 22685 20273 17457 18391>,
			<12591 22179 22619 19831 16616 17663>,
			<12530 14950 22589 19362 15968 16900>,
			<12543 12971 22882 19061 15860 16685>,
			<12835 13109 23733 18826 15915 16765>,
			<13149 13264 24263 18709 16013 16783>,
			<13262 13341 22660 19010 16324 16499>,
			<13333 13441 19772 19745 16911 16149>,
			<13426 13593 18461 20566 17680 16317>,
			<13571 13909 17794 21716 18907 17750>,
			<13682 14219 17513 22417 19920 19130>,
			<13695 14409 17804 22147 20571 19891>,
			<13660 14551 18297 21427 21071 20515>,
			<13599 14620 18368 20568 21098 20947>,
			<13396 14658 18054 19258 20686 21436>,
			<13133 14679 17544 18257 20184 21691>,
			<12914 14659 16342 18005 19798 21371>,
			<12748 14535 15022 17839 19295 20771>,
			<12852 14107 14458 17206 17894 19529>,
			<13083 13676 14337 16919 17022 18761>,
			<13418 13619 14430 17560 16205 17401>,
			<13520 13526 14068 17256 17342 16761>,
			<13515 13640 14167 17508 17572 16412>,
			<13798 13904 14297 17467 17205 16309>,
			<14033 14051 14495 18979 17134 15730>,
			<13433 13975 14572 18897 17695 16540>,
			<11673 13878 14227 18696 18925 16088>,
			<10113 12571 13867 18704 19032 16055>,
			<9233 10559 13140 19134 20434 22292>,
			<9233 10559 13140 19134 20434 22292>,
			<9233 10559 13140 19134 20434 22292>;
	};

	qcom,pc-temp-y6-lut {
		qcom,lut-col-legend = <(-10) 0 10 25 40 50>;
		qcom,lut-row-legend = <10000 9800 9600 9400 9200 9000>,
			<8800 8600 8400 8200 8000 7800>,
			<7600 7400 7200 7000 6800 6600>,
			<6400 6200 6000 5800 5600 5400>,
			<5200 5000 4800 4600 4400 4200>,
			<4000 3800 3600 3400 3200 3000>,
			<2800 2600 2400 2200 2000 1800>,
			<1600 1400 1200 1000 900 800>,
			<700 600 500 400 300 200>,
			<100 0>;
		qcom,lut-data = <6059 5504 5211 5042 4995 4986>,
			<6116 5534 5230 5042 4996 4987>,
			<6153 5564 5246 5043 4998 4988>,
			<6173 5589 5258 5044 4999 4989>,
			<6181 5607 5265 5045 5000 4990>,
			<6183 5614 5268 5045 5001 4990>,
			<6170 5610 5264 5045 5001 4991>,
			<6145 5600 5258 5045 5002 4992>,
			<6128 5592 5253 5046 5003 4993>,
			<6114 5584 5249 5048 5004 4994>,
			<6107 5576 5247 5051 5006 4995>,
			<6111 5567 5244 5053 5007 4996>,
			<6117 5558 5243 5055 5009 4997>,
			<6116 5561 5242 5058 5011 4999>,
			<6091 5589 5244 5061 5014 5001>,
			<6056 5608 5247 5065 5016 5003>,
			<6008 5584 5253 5069 5019 5005>,
			<5952 5537 5262 5074 5023 5008>,
			<5933 5514 5260 5080 5028 5011>,
			<5929 5504 5240 5087 5035 5017>,
			<5925 5495 5218 5091 5039 5021>,
			<5912 5483 5202 5078 5031 5015>,
			<5894 5471 5188 5054 5016 5004>,
			<5891 5462 5180 5044 5007 4997>,
			<5914 5454 5174 5038 5000 4991>,
			<5945 5450 5170 5036 4997 4988>,
			<5971 5450 5170 5037 4997 4988>,
			<5998 5452 5169 5038 4999 4989>,
			<6029 5459 5169 5040 5000 4990>,
			<6064 5490 5168 5042 5003 4993>,
			<6099 5532 5167 5044 5006 4995>,
			<6130 5572 5167 5047 5010 4998>,
			<6159 5615 5167 5051 5013 5001>,
			<6191 5664 5170 5053 5015 5003>,
			<6230 5720 5184 5054 5015 5004>,
			<6268 5781 5204 5055 5016 5004>,
			<6298 5850 5226 5053 5011 5001>,
			<6323 5926 5254 5049 5005 4995>,
			<6349 5997 5284 5049 5003 4994>,
			<6374 6066 5315 5050 5004 4994>,
			<6400 6125 5349 5052 5004 4995>,
			<6427 6167 5383 5056 5005 4997>,
			<6457 6201 5420 5062 5007 4998>,
			<6507 6231 5462 5065 5002 4991>,
			<6576 6268 5514 5071 5002 4990>,
			<6606 6273 5511 5074 5008 4998>,
			<6608 6289 5542 5079 5016 5008>,
			<6709 6360 5599 5090 5026 5019>,
			<6849 6434 5662 5103 5037 5029>,
			<7068 6528 5735 5114 5040 5027>,
			<7638 6653 5810 5101 5017 5003>,
			<9042 6868 5933 5104 5015 5002>,
			<12191 7573 6183 5125 5020 5005>,
			<20852 9702 6583 5159 5029 5016>,
			<20852 9702 6583 5159 5029 5016>,
			<20852 9702 6583 5159 5029 5016>;
	};

};
